AUTOSAR XML (schema 00050)
package /ComponentTypes
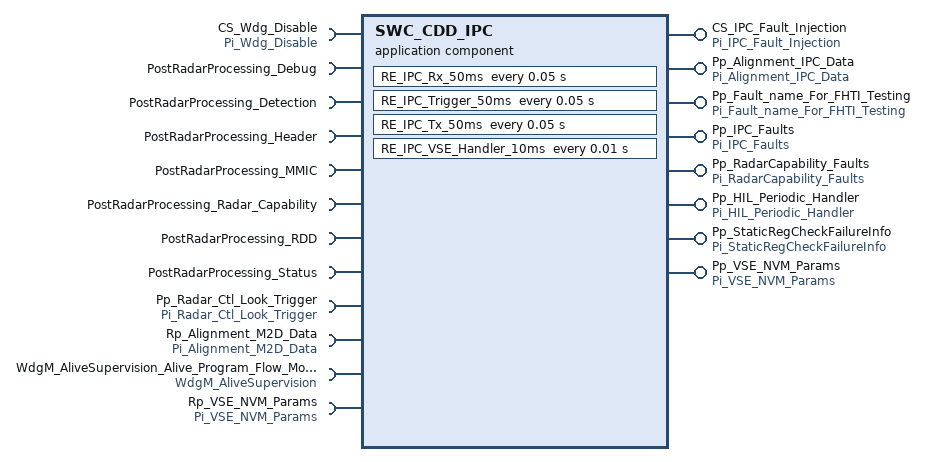
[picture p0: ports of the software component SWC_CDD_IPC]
  application sw component type SWC_CDD_IPC
    5 x provide port:
      CS_IPC_Fault_Injection: server-com-spec{operation=Read, queue-length=1}, provided-interface=Pi_IPC_Fault_Injection
      Pp_Alignment_IPC_Data: nonqueued-sender-com-spec{data-element=De_Alignment_IPC_Data, init-value=fields=[{short-label=dra_core_log_data, fields=[vacs_boresight_az_estimated:0, vacs_boresight_el_estimated:0, estimated_standard_deviation_az:0, estimated_standard_deviation_el:0, alignment_complete_percent_az:0, alignment_complete_percent_el:0, total_time_since_start:0, total_time_running_az_scf:0, total_time_running_el:0, total_distance_since_start:0, total_distance_running_az_scf:0, total_distance_running_el:0, avg_spd_since_start:0, avg_spd_running_az_scf:0, avg_spd_running_el:0, estimated_pos_error_bound_az:0, estimated_pos_error_bound_el:0, estimated_neg_error_bound_az:0, estimated_neg_error_bound_el:0, speed_compensation_factor_estimated:0, n_updates_azimuth:0, n_updates_elevation:0, detection_used_az:24 x 0, detection_used_el:24 x 0, alignment_mode:0, error_status_detection_input:0, azimuth_estimation_qf:0, elevation_estimation_qf:0, error_status_az_est_out_of_bounds:0, error_status_el_est_out_of_bounds:0, 0, error_status_excessive_blockage:0, error_status_vehicle_input:0, detection_coordinate_system:0, error_status_scf_out_of_bounds:0, error_status_combined:0, error_status_interference:0, scf_estimation_qf:0, n_updates_roll:0, 0, vacs_boresight_roll_kf_internal:0, vacs_boresight_roll_estimated:0, el_roll_kf_covariance:[0, 0, 0, 0], alignment_index:0, vacs_boresight_az_kf_internal:0, vacs_boresight_el_kf_internal:0, estimated_standard_deviation_rl:0, estimated_pos_error_bound_rl:0, estimated_neg_error_bound_rl:0, num_cycles_since_well_converged:0, flag_well_converged_az_el:0, interference_detected:0, blockage_active:0, coordinate_system:0, error_status_sudden_state_change:0, error_status_parking_accident:0, vacs_boresight_az_nominal:0, vacs_boresight_el_nominal:0, error_status_trailer_detected:0]}, {short-label=sra_core_log_data, fields=[vacs_boresight_az_nominal:0, vacs_boresight_az_estimated:0, vacs_boresight_el_nominal:0, vacs_boresight_el_estimated:0, estimated_standard_deviation_az:0, estimated_standard_deviation_el:0, target_mean_azimuth:0, target_mean_elevation:0, target_mean_range:0, target_mean_r_dot:0, target_mean_raw_amp:0, target_mean_snr:0, target_std_dev_azimuth:0, target_std_dev_elevation:0, target_std_dev_range:0, target_std_dev_r_dot:0, target_std_dev_raw_amp:0, target_std_dev_snr:0, complete_percentage:0, n_updates_az_el:0, AlgoStatus:0, ErrorAzimuthEstimate:0, ErrorElevationEstimate:0, ErrorStatusInterference:0, ErrorStatusIntialisation:0, ErrorStatusDetection:0, ErrorStatusVehical:0, f_interference_detected:0, az_qf:0, el_qf:0, alignment_mode:0]}, {short-label=alignment_static, fields=[StatusOfPlate:0, StatusOfAzimuth:0, StatusOfElevation:0]}, {short-label=veh_info, fields=[veh_speed:0, veh_yaw:0, veh_speed_qf:0, veh_yaw_qf:0, lros_drive_reverse:0]}, {short-label=alignment_stream, fields=[horiz_misalign_ang:0, vert_misalign_ang:0, std_azimuth:0, std_elevation:0, meas_plate_range:0, meas_plate_r_dot:0, meas_plate_rcs:0, std_range:0, std_r_dot:0, complete_percentage:0, status_of_plate:0, status_horiz_misalign_ang:0, status_vert_misalign_ang:0]}, alignment_mode:0, interference_detected:0, blockage_active:0, operation_mode_status:0, data_qualifier:0, look_index:0]}, provided-interface=Pi_Alignment_IPC_Data
      Pp_Fault_name_For_FHTI_Testing: nonqueued-sender-com-spec{data-element=De_Fault_name_FHTI, init-value=0}, provided-interface=Pi_Fault_name_For_FHTI_Testing
      Pp_IPC_Faults: nonqueued-sender-com-spec{data-element=De_IPC_Faults, init-value=fields=[IPC_M2D_Crc_Err_Cnt:0, IPC_D2M_Crc_Err_Cnt:0, IPC_D2A_Crc_Err_Cnt:0, IPC_A2M_Crc_Err_Cnt:0]}, provided-interface=Pi_IPC_Faults
      Pp_RadarCapability_Faults: nonqueued-sender-com-spec{data-element=De_RadarCapability_Faults, init-value=constant-reference=C_RadarCapability}, provided-interface=Pi_RadarCapability_Faults
    11 x require port:
      CS_Wdg_Disable: client-com-spec=Read, required-interface=Pi_Wdg_Disable
      PostRadarProcessing_Debug: client-com-spec=Populate_Debug_Stream, required-interface=PostRadarProcessing_Debug
      PostRadarProcessing_Detection: client-com-spec=Populate_Detection_Stream, required-interface=PostRadarProcessing_Detection
      PostRadarProcessing_Header: client-com-spec=Populate_Header_Stream, required-interface=PostRadarProcessing_Header
      PostRadarProcessing_MMIC: client-com-spec=Populate_MMIC_Stream, required-interface=PostRadarProcessing_MMIC
      PostRadarProcessing_Radar_Capability: client-com-spec=Populate_Radar_Capability_Stream, required-interface=PostRadarProcessing_Radar_Capability
      PostRadarProcessing_RDD: client-com-spec=Populate_RDD_Stream, required-interface=PostRadarProcessing_RDD
      PostRadarProcessing_Status: client-com-spec=Populate_Status_Stream, required-interface=PostRadarProcessing_Status
      Pp_Radar_Ctl_Look_Trigger: client-com-spec=Operation, required-interface=Pi_Radar_Ctl_Look_Trigger
      Rp_Alignment_M2D_Data: nonqueued-receiver-com-spec{data-element=De_Alignment_M2D_Data, filter=data-filter-type=ALWAYS, init-value=fields=[{short-label=static_alignment_data, fields=[yaw:0, pitch:0, plate_angle_deg_scs:0, plate_distance:0, polarity:0, horz_angle_min:0, horz_angle_max:0, vert_angle_min:0, vert_angle_max:0, plate_lat_position:0, mount_loc:0, align_cmd:0, max_abs_misalignment_az:0, max_abs_misalignment_el_sky:0, max_abs_misalignment_el_ground:0, target_height_over_ground:0, k_num_valid_scan_needed:0, k_max_number_of_scans_allowed:0, target_range_rate:0, target_type_select:0, f_data_valid:0]}, {short-label=dynamic_alignment_data, fields=[0, 0, 0, max_abs_misalignment_az:0, short_track_target_height:0, short_track_target_range_rate:0, az_scf_kf_covariance:[0, 0, 0, 0], el_kf_covariance:0, iso_sensor_x_posn:0, iso_sensor_y_posn:0, iso_sensor_z_posn:0, iso_sensor_yaw:0, iso_sensor_pitch:0, iso_sensor_roll:0, distance_rear_axle_to_front_bumper:0, max_abs_misalignment_el_sky:0, max_abs_misalignment_el_ground:0, aacurrent_azimuth:0, aacurrent_elevation:0, 0, 0, mount_loc:0, short_track_exit_condition:0, f_data_valid:0, 0, 0, align_cmd:0, auto_align_status:0, 0, 0, el_roll_kf_covariance:[0, 0, 0, 0], Align_RadarOperation_Mode:0, coordinate_system_input:0]}]}, required-interface=Pi_Alignment_M2D_Data
      WdgM_AliveSupervision_Alive_Program_Flow_Monitoring: client-com-spec=CheckpointReached, required-interface=WdgM_AliveSupervision
    provide port Pp_HIL_Periodic_Handler: provided-interface=Pi_HIL_Periodic_Handler
    provide port Pp_StaticRegCheckFailureInfo: nonqueued-sender-com-spec{data-element=De_StaticRegCheckFailureInfo, init-value=35 x 0}, provided-interface=Pi_StaticRegCheckFailureInfo
    require port Rp_VSE_NVM_Params: nonqueued-receiver-com-spec{data-element=De_VSE_NVM_Params, filter=data-filter-type=ALWAYS, init-value=fields=[nvm_last_rem_swa_bias_deg:0, nvm_last_rem_speed_comp:0, nvm_last_rem_stop_yaw_bias_primary_radps:0, nvm_last_rem_stop_yaw_bias_secondary_radps:0, nvm_f_last_rem_swa_bias:0]}, required-interface=Pi_VSE_NVM_Params
    provide port Pp_VSE_NVM_Params: nonqueued-sender-com-spec{data-element=De_VSE_NVM_Params, init-value=fields=[nvm_last_rem_swa_bias_deg:0, nvm_last_rem_speed_comp:0, nvm_last_rem_stop_yaw_bias_primary_radps:0, nvm_last_rem_stop_yaw_bias_secondary_radps:0, nvm_f_last_rem_swa_bias:0]}, provided-interface=Pi_VSE_NVM_Params
    behavior SWC_CDD_IPC_InternalBehavior: handle-termination-and-restart=NO-SUPPORT
      operation invoked event OIT_CS_IPC_Fault_Injection_Read_CS_IPC_Fault_Injection_Read: start-on-event=CS_IPC_Fault_Injection, operation=CS_IPC_Fault_Injection.Read
      timing event TMT_RE_IPC_Rx_50ms: start-on-event=RE_IPC_Rx_50ms, period=0.05
      timing event TMT_RE_IPC_Trigger_50ms: start-on-event=RE_IPC_Trigger_50ms, period=0.05
      timing event TMT_RE_IPC_Tx_50ms: start-on-event=RE_IPC_Tx_50ms, period=0.05
      internal trigger occurred event ITOE_Dsp_sp_post_processing_complete_ITP_RE_IPC_Trigger_50ms_Dsp_sp_post_processing_complete: start-on-event=Dsp_sp_post_processing_complete, event-source=ITP_RE_IPC_Trigger_50ms_Dsp_sp_post_processing_complete
      init event RE_CDD_IPC_InitEvent: start-on-event=RE_CDD_IPC_Init
      timing event TMT_RE_IPC_VSE_Handler_10ms: start-on-event=RE_IPC_VSE_Handler_10ms, period=0.01
      7 x runnable:
        CS_IPC_Fault_Injection
        RE_IPC_Rx_50ms: external-triggering-point=Pp_HIL_Periodic_Handler.Trigger
          data-receive-point-by-arguments:
            access REC_Rp_Alignment_M2D_Data_De_Alignment_M2D_Data: accessed-variable=Rp_Alignment_M2D_Data.De_Alignment_M2D_Data
          sync call SC_WdgM_AliveSupervision_Alive_Program_Flow_Monitoring_CheckpointReached: operation=WdgM_AliveSupervision_Alive_Program_Flow_Monitoring.CheckpointReached
        RE_IPC_Trigger_50ms
          data-send-points:
            access SEND_Pp_Fault_name_For_FHTI_Testing_De_Fault_name_FHTI: accessed-variable=Pp_Fault_name_For_FHTI_Testing.De_Fault_name_FHTI
          internal triggering point ITP_RE_IPC_Trigger_50ms
          internal triggering point ITP_RE_IPC_Trigger_50ms_Dsp_sp_post_processing_complete
          7 x async call:
            AC_PostRadarProcessing_Debug_Populate_Debug_Stream: operation=PostRadarProcessing_Debug.Populate_Debug_Stream
            AC_PostRadarProcessing_Detection_Populate_Detection_Stream: operation=PostRadarProcessing_Detection.Populate_Detection_Stream
            AC_PostRadarProcessing_Header_Populate_Header_Stream: operation=PostRadarProcessing_Header.Populate_Header_Stream
            AC_PostRadarProcessing_Radar_Capability_Populate_Radar_Capability_Stream: operation=PostRadarProcessing_Radar_Capability.Populate_Radar_Capability_Stream
            AC_PostRadarProcessing_RDD_Populate_RDD_Stream: operation=PostRadarProcessing_RDD.Populate_RDD_Stream
            AC_PostRadarProcessing_Status_Populate_Status_Stream: operation=PostRadarProcessing_Status.Populate_Status_Stream
            AC_Pp_Radar_Ctl_Look_Trigger_Operation: operation=Pp_Radar_Ctl_Look_Trigger.Operation
          sync call SC_CS_Wdg_Disable_Read: operation=CS_Wdg_Disable.Read
        RE_IPC_Tx_50ms
          data-receive-point-by-arguments:
            access REC_Rp_VSE_NVM_Params_De_VSE_NVM_Params: accessed-variable=Rp_VSE_NVM_Params.De_VSE_NVM_Params
          data-send-points:
            5 x access:
              SEND_Pp_Alignment_IPC_Data_De_Alignment_IPC_Data: accessed-variable=Pp_Alignment_IPC_Data.De_Alignment_IPC_Data
              SEND_Pp_IPC_Faults_De_IPC_Faults: accessed-variable=Pp_IPC_Faults.De_IPC_Faults
              SEND_Pp_RadarCapability_Faults_De_RadarCapability_Faults: accessed-variable=Pp_RadarCapability_Faults.De_RadarCapability_Faults
              SEND_Pp_StaticRegCheckFailureInfo_De_StaticRegCheckFailureInfo: accessed-variable=Pp_StaticRegCheckFailureInfo.De_StaticRegCheckFailureInfo
              SEND_Pp_VSE_NVM_Params_De_VSE_NVM_Params: accessed-variable=Pp_VSE_NVM_Params.De_VSE_NVM_Params
        Dsp_sp_post_processing_complete
        RE_CDD_IPC_Init
        RE_IPC_VSE_Handler_10ms
  swc implementation SWC_CDD_IPC_Implementation: behavior=SWC_CDD_IPC_InternalBehavior
    code-descriptors:
      code Default: artifact-descriptors=autosar-engineering-object=category=SWSRC
